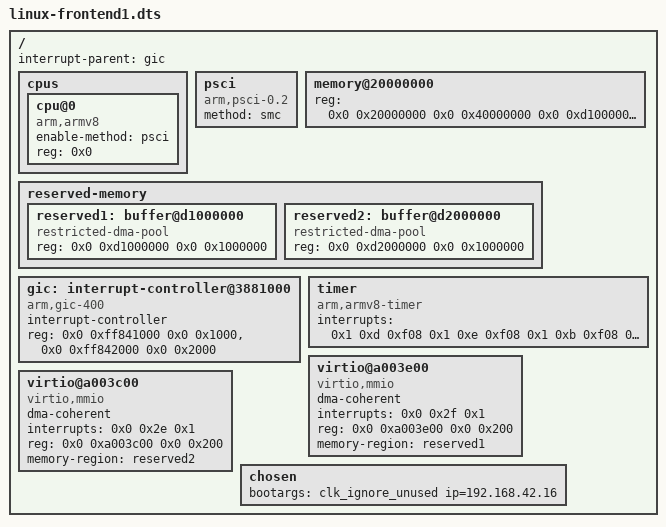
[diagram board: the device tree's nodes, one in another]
/dts-v1/;

/ {
	#address-cells = <2>;
	#size-cells = <2>;
	interrupt-parent = <&gic>;

	cpus {
		#size-cells = <0x0>;
		#address-cells = <0x1>;

		cpu@0 {
			compatible = "arm,armv8";
			device_type = "cpu";
			enable-method = "psci";
			reg = <0x0>;
		};	
	};

	psci {
		compatible = "arm,psci-0.2";
		method = "smc";
	};

	memory@20000000 {
		reg = <0x0 0x20000000 0x0 0x40000000
               0x0 0xd1000000 0x0 0x02000000>;
		device_type = "memory";
	};
 
    reserved-memory {
		#address-cells = <0x2>;
		#size-cells = <0x2>;
		ranges;
	
		reserved1: buffer@d1000000 {
		    compatible = "restricted-dma-pool";			
		    reg = <0x0 0xd1000000 0x0 0x1000000>;
		};

		reserved2: buffer@d2000000 {
		    compatible = "restricted-dma-pool";			
		    reg = <0x0 0xd2000000 0x0 0x1000000>;
		};
    };

	gic: interrupt-controller@3881000 {
		compatible = "arm,gic-400";
		#interrupt-cells = <3>;
		interrupt-controller;
		reg = <0x0 0xff841000 0x0 0x1000>,
		      <0x0 0xff842000 0x0 0x2000>;
	};

	timer {
		compatible = "arm,armv8-timer";
		interrupts = <0x1 0xd 0xf08 0x1 0xe 0xf08 0x1 0xb 0xf08 0x1 0xa 0xf08>;
	};
 	
    virtio@a003e00 {
		dma-coherent;
		interrupts = <0x0 0x2f 0x1>;
		reg = <0x0 0xa003e00 0x0 0x200>;
		compatible = "virtio,mmio";
		memory-region = <&reserved1>;	
	};

	virtio@a003c00 {
		dma-coherent;
		interrupts = <0x0 0x2e 0x1>;
		reg = <0x0 0xa003c00 0x0 0x200>;
		compatible = "virtio,mmio";
		memory-region = <&reserved2>;	
	};

	chosen {
		bootargs = "clk_ignore_unused ip=192.168.42.16";
	};

};
